# STM32H562 register map
File version: 1.8
CPU: CM33 r0p0, little endian, MPU, FPU, 4 interrupt priority bits
Registers are 32-bit, read-write, reset 0x0 unless marked. A register's access mark holds for its fields unless they carry their own. Offsets are from the block's base; [hi:lo] are bit positions.

## DCACHE — Data cache
Base 0x40031400
Same registers: SEC_DCACHE 0x50031400
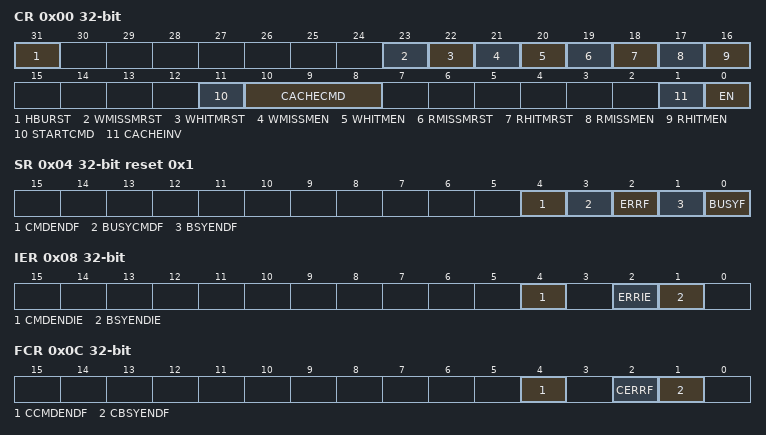
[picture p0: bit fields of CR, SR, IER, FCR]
0x00 CR access per field — DCACHE control register
  [31] HBURST rw — output burst type for cache master port read accesses Write access is always done in INCR burst type.
  [23] WMISSMRST rw — write-miss monitor reset
  [22] WHITMRST rw — write-hit monitor reset
  [21] WMISSMEN rw — write-miss monitor enable
  [20] WHITMEN rw — write-hit monitor enable
  [19] RMISSMRST rw — read-miss monitor reset
  [18] RHITMRST rw — read-hit monitor reset
  [17] RMISSMEN rw — read-miss monitor enable
  [16] RHITMEN rw — read-hit monitor enable
  [11] STARTCMD wo — starts maintenance command (maintenance operation defined in CACHECMD). Can be set by software, only when EN = 1, BUSYCMDF = 0, BUSYF = 0 and CACHECMD = 0b001, 0b010 or 0b011. Cleared by hardware when the BUSYCMDF flag is set (during cache maintenance operation). Writing 0 has no effect.
  [10:8] CACHECMD rw — cache command maintenance operation (cleans and/or invalidates an address range) Can be set and cleared by software, only when no maintenance command is ongoing (BUSYCMDF = 0). others: reserved
  [1] CACHEINV wo — full cache invalidation Can be set by software, only when EN = 1. Cleared by hardware when the BUSYF flag is set (during full cache invalidation operation). Writing 0 has no effect.
  [0] EN rw — enable
0x04 SR ro reset 0x1 — DCACHE status register
  [4] CMDENDF — command end flag Cleared by writing DCACHE_FCR.CCMDENDF = 1.
  [3] BUSYCMDF — command busy flag
  [2] ERRF — cache error flag Cleared by writing DCACHE_FCR.CERRF = 1.
  [1] BSYENDF — full invalidate busy end flag Cleared by writing DCACHE_FCR.CBSYENDF = 1.
  [0] BUSYF — full invalidate busy flag
0x08 IER — DCACHE interrupt enable register
  [4] CMDENDIE — interrupt enable on command end Set by software to enable an interrupt generation at the end of a cache command (clean and/or invalidate an address range)
  [2] ERRIE — interrupt enable on cache error Set by software to enable an interrupt generation in case of cache functional error (eviction or clean operation write-back error)
  [1] BSYENDIE — interrupt enable on busy end Set by SW to enable an interrupt generation at the end of a cache full invalidate operation.
0x0C FCR wo — DCACHE flag clear register
  [4] CCMDENDF — clear command end flag Set by software.
  [2] CERRF — clear cache error flag Set by software.
  [1] CBSYENDF — clear full invalidate busy end flag Set by software.
0x10 RHMONR ro — DCACHE read-hit monitor register
  [31:0] RHITMON — cache read-hit monitor counter
0x14 RMMONR ro — DCACHE read-miss monitor register
  [15:0] RMISSMON — cache read-miss monitor counter
0x20 WHMONR ro — DCACHE write-hit monitor register
  [31:0] WHITMON — cache write-hit monitor counter
0x24 WMMONR ro — DCACHE write-miss monitor register
  [15:0] WMISSMON — cache write-miss monitor counter
0x28 CMDRSADDRR — DCACHE command range start address register
  [31:4] CMDSTARTADDR — start address of range to which the cache maintenance command specified in DCACHE_CR.CACHECMD field applies This register must be set before DCACHE_CR.CACHECMD is written. .
0x2C CMDREADDRR — DCACHE command range end address register
  [31:4] CMDENDADDR — end address of range to which the cache maintenance command specified in DCACHE_CR.CACHECMD field applies This register must be set before DCACHE_CR.CACHECMD is written.

## DLYBOS1 — Delay block
Base 0x4600F000
Same registers: DLYBSD1 0x46008400, DLYBSD2 0x46008800, SEC_DLYBSD1 0x56008400, SEC_DLYBSD2 0x56008800, SEC_DLYBOS1 0x5600F000
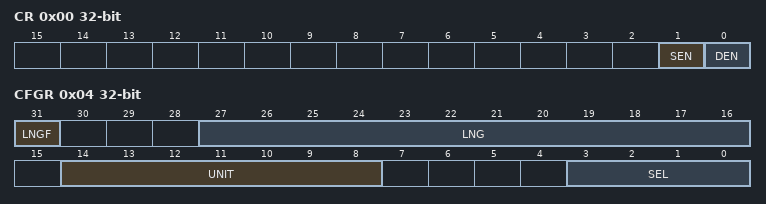
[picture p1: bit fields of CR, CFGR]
0x00 CR — control register
  [1] SEN — OPALPM
  [0] DEN — Operational amplifier Enable
0x04 CFGR access per field — configuration register
  [31] LNGF ro, [27:16] LNG ro, [14:8] UNIT rw, [3:0] SEL rw
